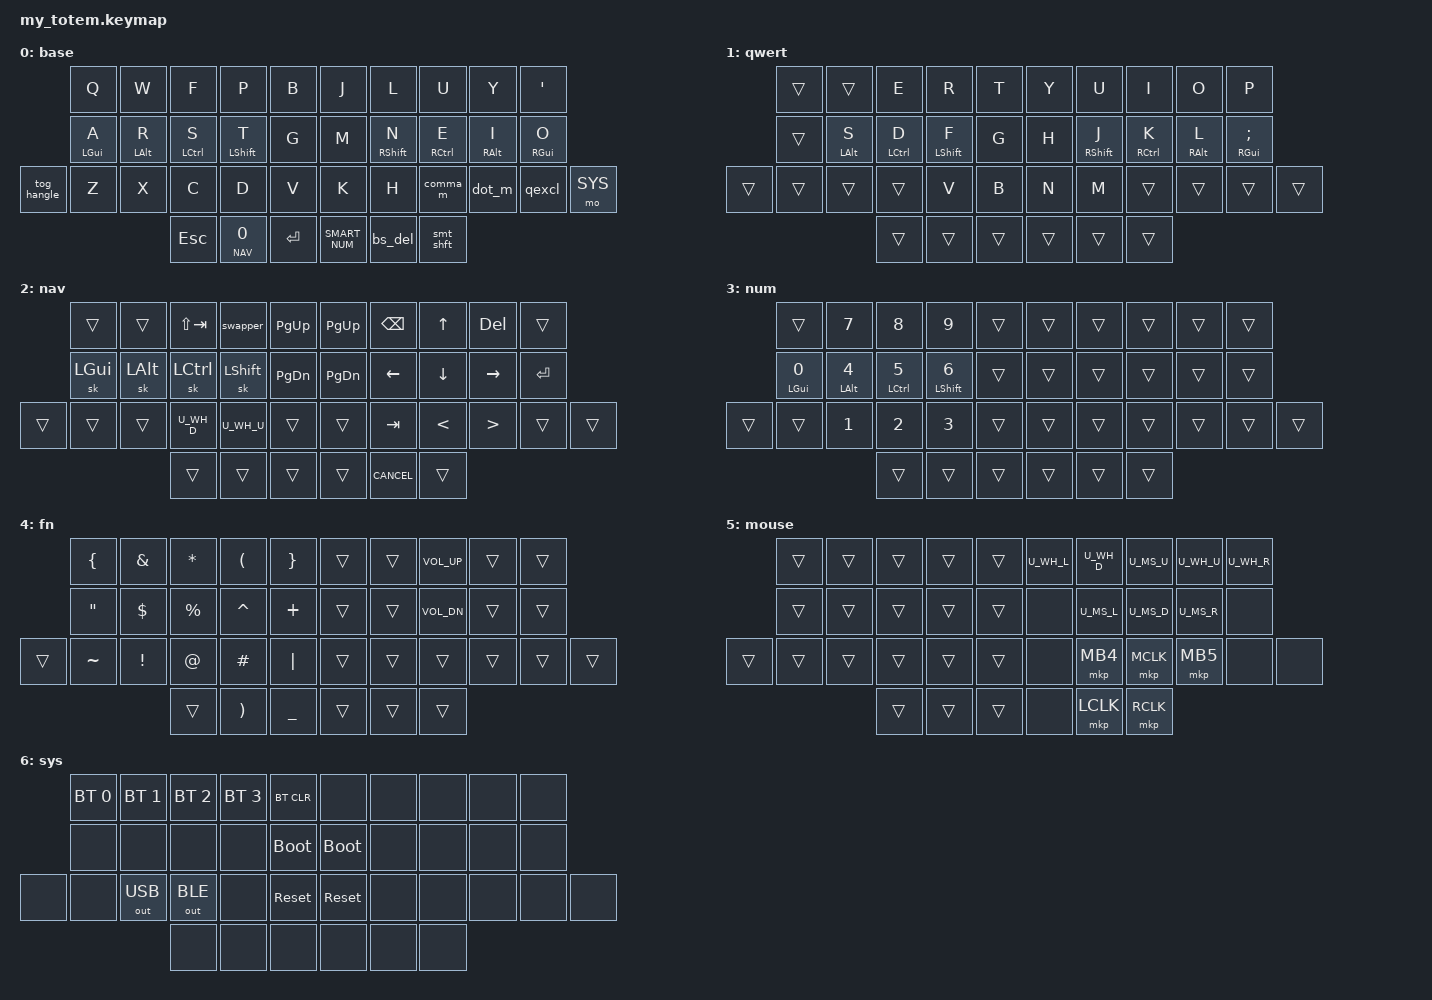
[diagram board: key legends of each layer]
//
//                                                        ▀▀▀▀▀     ▀▀▀▀▀          ▀▀█▀▀
//                                                        ▄▀▀▀▄  ▄  ▄▀▀▀▄  ▄  ▄▀▀▀▄  █  ▄▀▀▀▄
//                                                        █   █  █  █   █  █  █   █  █  █   █
//                                                         ▀▀▀   █   ▀▀▀   █   ▀▀▀   ▀   ▀▀▀
//                                                               █      ▄▄▄█▄▄▄    █   █  
//                                                               ▀      █  █  █     █▄█
//                                                             ▀▀▀▀▀    █  █  █      ▀
//                                                                      ▀  ▀  ▀
//
// ▄▄▄▄▄▄▄▄▄▄▄▄▄▄▄▄▄▄▄▄▄▄▄▄▄▄▄▄▄▄▄▄▄▄▄▄▄▄▄▄▄▄▄▄▄▄▄▄▄▄▄▄▄▄▄▄▄▄▄▄▄▄▄▄▄▄▄▄▄▄▄▄▄▄▄▄▄▄▄▄▄▄▄▄▄▄▄▄▄▄▄▄▄▄▄▄▄▄▄▄▄▄▄▄▄▄▄▄▄▄▄▄▄▄▄▄▄▄▄▄▄▄▄▄▄▄▄▄▄▄▄▄▄▄▄▄▄▄▄▄▄▄▄▄▄▄▄▄▄

#include <behaviors.dtsi>
#include <dt-bindings/zmk/bt.h>
#include <dt-bindings/zmk/keys.h>
#include <dt-bindings/zmk/outputs.h>
#include "keypos_38keys.h"

#include "zmk-helpers/helper.h"

#define BASE 0
#define QWERT 1
#define NAV 2
#define NUM 3
#define FN 4
#define MOUSE 5
#define SYS 6

#define KEYS_L LT0 LT1 LT2 LT3 LT4 LM0 LM1 LM2 LM3 LM4 LB0 LB1 LB2 LB3 LB4 LB5  // left hand
#define KEYS_R RT0 RT1 RT2 RT3 RT4 RM0 RM1 RM2 RM3 RM4 RB0 RB1 RB2 RB3 RB4 RB5  // right hand
#define THUMBS LH2 LH1 LH0 RH0 RH1 RH2                                          // thumbs
                                                                                
#include "combos.dtsi"
#include "mouse.dtsi"

#define XXX &none
#define ___ &trans

/* Global settings */
#define QUICK_TAP_MS 175
#define TAPPING_TERM_MS 200

#include "behaviors.dtsi"
#include "macros.dtsi"

/* Nav cluster */
#define NAV_LEFT  &mt_home 0   LEFT    // tap: left  | long-tap: beginning of line
#define NAV_RIGHT &mt_end 0    RIGHT   // tap: right | long-tap: end       of line
#define NAV_UP    &mt LC(HOME) UP      // tap: up    | long-tap: beginning of document
#define NAV_DOWN  &mt LC(END)  DOWN    // tap: down  | long-tap: end       of document
#define NAV_BSPC  &mt LC(BSPC) BSPC    // tap: bspc  | long-tap: delete word backward
#define NAV_DEL   &mt LC(DEL)  DEL     // tap: del   | long-tap: delete word forward

ZMK_CONDITIONAL_LAYER(FN NUM, SYS)     // FN + NUM --> SYS

ZMK_LAYER(base,
//                 ╭───────────────┬───────────────┬───────────────┬───────────────┬───────────────╮   ╭───────────────┬───────────────┬───────────────┬───────────────┬───────────────╮
                     &kp Q           &kp W           &kp F           &kp P           &kp B               &kp J           &kp L           &kp U           &kp Y           &kp SQT
//                 ├───────────────┼───────────────┼───────────────┼───────────────┼───────────────┤   ├───────────────├───────────────┼───────────────┼───────────────┼───────────────┤
                     &hml LGUI A     &hml LALT R     &hml LCTRL S    &hml LSHFT T    &kp G               &kp M           &hmr RSHFT N    &hmr RCTRL E    &hmr RALT I     &hmr RGUI O
// ╭───────────────┼───────────────┼───────────────┼───────────────┼───────────────┼───────────────┤   ├───────────────├───────────────┼───────────────┼───────────────┼───────────────┤───────────────╮
     &tog_hangle     &kp Z           &kp X           &kp C           &kp D           &kp V               &kp K           &kp H           &comma_m        &dot_m          &qexcl          &mo SYS
// ╰───────────────┴───────────────┴───────────────┼───────────────┼───────────────┼───────────────┤   ├───────────────├───────────────┼───────────────┼───────────────┴───────────────┴───────────────╯
                                                     &kp ESC         &lt_spc NAV 0   &kp  RETURN        SMART_NUM       &bs_del         &smt_shft
//                                                 ╰───────────────┴───────────────┴───────────────╯   ╰───────────────┴───────────────┴───────────────╯
)
ZMK_LAYER(qwert,
//                 ╭───────────────┬───────────────┬───────────────┬───────────────┬───────────────╮   ╭───────────────┬───────────────┬───────────────┬───────────────┬───────────────╮
                     ___             ___             &kp E           &kp R           &kp T               &kp Y           &kp U           &kp I           &kp O           &kp P
//                 ├───────────────┼───────────────┼───────────────┼───────────────┼───────────────┤   ├───────────────├───────────────┼───────────────┼───────────────┼───────────────┤
                     ___             &hml LALT S     &hml LCTRL D    &hml LSHFT F    &kp G               &kp H           &hmr RSHFT J    &hmr RCTRL K    &hmr RALT L    &hmr RGUI SEMI
// ╭───────────────┼───────────────┼───────────────┼───────────────┼───────────────┼───────────────┤   ├───────────────├───────────────┼───────────────┼───────────────┼───────────────┤───────────────╮
     ___             ___             ___             ___             &kp V           &kp B               &kp N           &kp M           ___             ___             ___             ___
// ╰───────────────┴───────────────┴───────────────┼───────────────┼───────────────┼───────────────┤   ├───────────────├───────────────┼───────────────┼───────────────┴───────────────┴───────────────╯
                                                     ___             ___             ___                 ___             ___             ___
//                                                 ╰───────────────┴───────────────┴───────────────╯   ╰───────────────┴───────────────┴───────────────╯
)

ZMK_LAYER(nav,
//                 ╭───────────────┬───────────────┬───────────────┬───────────────┬───────────────╮   ╭───────────────┬───────────────┬───────────────┬───────────────┬───────────────╮
                     ___             ___             &kp LS(TAB)     &swapper        &kp PG_UP           &kp PG_UP       &kp BSPC        &kp UP          &kp DEL         ___
//                 ├───────────────┼───────────────┼───────────────┼───────────────┼───────────────┤   ├───────────────├───────────────┼───────────────┼───────────────┼───────────────┤
                     &sk LGUI        &sk LALT        &sk LCTRL       &sk LSHIFT      &kp PG_DN           &kp PG_DN       &kp LEFT        &kp DOWN        &kp RIGHT       &kp RET
// ╭───────────────┼───────────────┼───────────────┼───────────────┼───────────────┼───────────────┤   ├───────────────├───────────────┼───────────────┼───────────────┼───────────────┤───────────────╮
     ___             ___             ___             U_WH_D          U_WH_U          ___                 ___             &kp TAB         &kp LT          &kp GT          ___             ___
// ╰───────────────┴───────────────┴───────────────┼───────────────┼───────────────┼───────────────┤   ├───────────────├───────────────┼───────────────┼───────────────┴───────────────┴───────────────╯
                                                     ___             ___             ___                 ___             &kp K_CANCEL    ___
//                                                 ╰───────────────┴───────────────┴───────────────╯   ╰───────────────┴───────────────┴───────────────╯
)
ZMK_LAYER(num,
//                 ╭───────────────┬───────────────┬───────────────┬───────────────┬───────────────╮   ╭───────────────┬───────────────┬───────────────┬───────────────┬───────────────╮
                     ___             &kp N7          &kp N8          &kp N9          ___                 ___             ___             ___             ___             ___
//                 ├───────────────┼───────────────┼───────────────┼───────────────┼───────────────┤   ├───────────────├───────────────┼───────────────┼───────────────┼───────────────┤
                     &hml LGUI N0    &hml LALT N4    &hml LCTRL N5   &hml LSHFT N6   ___                 ___             ___             ___             ___             ___
// ╭───────────────┼───────────────┼───────────────┼───────────────┼───────────────┼───────────────┤   ├───────────────├───────────────┼───────────────┼───────────────┼───────────────┤───────────────╮
     ___             ___             &kp N1          &kp N2          &kp N3          ___                 ___             ___             ___             ___             ___             ___
// ╰───────────────┴───────────────┴───────────────┼───────────────┼───────────────┼───────────────┤   ├───────────────├───────────────┼───────────────┼───────────────┴───────────────┴───────────────╯
                                                     ___             ___             ___                 ___             ___             ___
//                                                 ╰───────────────┴───────────────┴───────────────╯   ╰───────────────┴───────────────┴───────────────╯
)
ZMK_LAYER(fn,
//                 ╭───────────────┬───────────────┬───────────────┬───────────────┬───────────────╮   ╭───────────────┬───────────────┬───────────────┬───────────────┬───────────────╮
                     &kp LBRC        &kp AMPS        &kp ASTRK       &kp LPAR        &kp RBRC            ___             ___             &kp C_VOL_UP    ___             ___
//                 ├───────────────┼───────────────┼───────────────┼───────────────┼───────────────┤   ├───────────────├───────────────┼───────────────┼───────────────┼───────────────┤
                     &kp DQT         &kp DLLR        &kp PRCNT       &kp CARET       &kp PLUS            ___             ___             &kp C_VOL_DN    ___             ___
// ╭───────────────┼───────────────┼───────────────┼───────────────┼───────────────┼───────────────┤   ├───────────────├───────────────┼───────────────┼───────────────┼───────────────┤───────────────╮
     ___             &kp TILDE       &kp EXCL        &kp AT_SIGN     &kp HASH        &kp PIPE            ___             ___             ___             ___             ___             ___
// ╰───────────────┴───────────────┴───────────────┼───────────────┼───────────────┼───────────────┤   ├───────────────├───────────────┼───────────────┼───────────────┴───────────────┴───────────────╯
                                                     ___             &kp RPAR        &kp UNDER           ___             ___             ___
//                                                 ╰───────────────┴───────────────┴───────────────╯   ╰───────────────┴───────────────┴───────────────╯
)
ZMK_LAYER(mouse,
//                 ╭───────────────┬───────────────┬───────────────┬───────────────┬───────────────╮   ╭───────────────┬───────────────┬───────────────┬───────────────┬───────────────╮
                     ___             ___             ___             ___             ___                 U_WH_L          U_WH_D          U_MS_U          U_WH_U          U_WH_R  
//                 ├───────────────┼───────────────┼───────────────┼───────────────┼───────────────┤   ├───────────────├───────────────┼───────────────┼───────────────┼───────────────┤
                     ___             ___             ___             ___             ___                 XXX             U_MS_L          U_MS_D          U_MS_R          XXX  
// ╭───────────────┼───────────────┼───────────────┼───────────────┼───────────────┼───────────────┤   ├───────────────├───────────────┼───────────────┼───────────────┼───────────────┤───────────────╮
     ___             ___             ___             ___             ___             ___                 XXX             &mkp MB4        &mkp MCLK       &mkp MB5        XXX             XXX
// ╰───────────────┴───────────────┴───────────────┼───────────────┼───────────────┼───────────────┤   ├───────────────├───────────────┼───────────────┼───────────────┴───────────────┴───────────────╯
                                                     ___             ___             ___                 XXX             &mkp LCLK       &mkp RCLK
//                                                 ╰───────────────┴───────────────┴───────────────╯   ╰───────────────┴───────────────┴───────────────╯

)
ZMK_LAYER(sys,
//                 ╭───────────────┬───────────────┬───────────────┬───────────────┬───────────────╮   ╭───────────────┬───────────────┬───────────────┬───────────────┬───────────────╮
                     &bt BT_SEL 0    &bt BT_SEL 1    &bt BT_SEL 2    &bt BT_SEL 3    &bt BT_CLR          XXX             XXX             XXX             XXX             XXX
//                 ├───────────────┼───────────────┼───────────────┼───────────────┼───────────────┤   ├───────────────├───────────────┼───────────────┼───────────────┼───────────────┤
                     XXX             XXX             XXX             XXX             &bootloader         &bootloader     XXX             XXX             XXX             XXX
// ╭───────────────┼───────────────┼───────────────┼───────────────┼───────────────┼───────────────┤   ├───────────────├───────────────┼───────────────┼───────────────┼───────────────┤───────────────╮
     XXX             XXX             &out OUT_USB    &out OUT_BLE    XXX             &sys_reset          &sys_reset      XXX             XXX             XXX             XXX             XXX
// ╰───────────────┴───────────────┴───────────────┼───────────────┼───────────────┼───────────────┤   ├───────────────├───────────────┼───────────────┼───────────────┴───────────────┴───────────────╯
                                                     XXX             XXX             XXX                 XXX             XXX             XXX
//                                                 ╰───────────────┴───────────────┴───────────────╯   ╰───────────────┴───────────────┴───────────────╯
)
// / {
//     keymap {
//         compatible = "zmk,keymap";
// // ▄▄▄▄▄▄▄▄▄▄▄▄▄▄▄▄▄▄▄▄▄▄▄▄▄▄▄▄▄▄▄▄▄▄▄▄▄▄▄▄▄▄▄▄▄▄▄▄▄▄▄▄▄▄▄▄▄▄▄▄▄▄▄▄▄▄▄▄▄▄▄▄▄▄▄▄▄▄▄▄▄▄▄▄▄▄▄▄▄▄▄▄▄▄▄▄▄▄▄▄▄▄▄▄▄▄▄▄▄▄▄▄▄▄▄▄▄▄▄▄▄▄▄▄▄▄▄▄▄▄▄▄▄▄▄▄▄▄▄▄▄▄▄▄▄▄▄▄▄
//
//         base_layer {
//             bindings = <
// //                 ╭───────────────┬───────────────┬───────────────┬───────────────┬───────────────╮   ╭───────────────┬───────────────┬───────────────┬───────────────┬───────────────╮
//                      &kp Q           &kp W           &kp F           &kp P           &kp B               &kp J           &kp L           &kp U           &kp Y           &kp SQT
// //                 ├───────────────┼───────────────┼───────────────┼───────────────┼───────────────┤   ├───────────────├───────────────┼───────────────┼───────────────┼───────────────┤
//                      &hml LGUI A     &hml LALT R     &hml LCTRL S    &hml LSHFT T    &kp G               &kp M           &hmr RSHFT N    &hmr RCTRL E    &hmr RALT I     &hmr RGUI O
// // ╭───────────────┼───────────────┼───────────────┼───────────────┼───────────────┼───────────────┤   ├───────────────├───────────────┼───────────────┼───────────────┼───────────────┤───────────────╮
//      &tog_hangle     &kp Z           &kp X           &kp C           &kp D           &kp V               &kp K           &kp H           &comma_m        &dot_m          &qexcl          &mo SYS
// // ╰───────────────┴───────────────┴───────────────┼───────────────┼───────────────┼───────────────┤   ├───────────────├───────────────┼───────────────┼───────────────┴───────────────┴───────────────╯
//                                                      &kp ESC         &lt_spc NAV 0   &kp  RETURN        SMART_NUM       &bs_del         &smt_shft
// //                                                 ╰───────────────┴───────────────┴───────────────╯   ╰───────────────┴───────────────┴───────────────╯
//             >;
//         };
// // ▄▄▄▄▄▄▄▄▄▄▄▄▄▄▄▄▄▄▄▄▄▄▄▄▄▄▄▄▄▄▄▄▄▄▄▄▄▄▄▄▄▄▄▄▄▄▄▄▄▄▄▄▄▄▄▄▄▄▄▄▄▄▄▄▄▄▄▄▄▄▄▄▄▄▄▄▄▄▄▄▄▄▄▄▄▄▄▄▄▄▄▄▄▄▄▄▄▄▄▄▄▄▄▄▄▄▄▄▄▄▄▄▄▄▄▄▄▄▄▄▄▄▄▄▄▄▄▄▄▄▄▄▄▄▄▄▄▄▄▄▄▄▄▄▄▄▄▄▄
//
//         qwert_layout {
//             bindings = <
// //                 ╭───────────────┬───────────────┬───────────────┬───────────────┬───────────────╮   ╭───────────────┬───────────────┬───────────────┬───────────────┬───────────────╮
//                      ___             ___             &kp E           &kp R           &kp T               &kp Y           &kp U           &kp I           &kp O           &kp P
// //                 ├───────────────┼───────────────┼───────────────┼───────────────┼───────────────┤   ├───────────────├───────────────┼───────────────┼───────────────┼───────────────┤
//                      ___             &hml LALT S     &hml LCTRL D    &hml LSHFT F    &kp G               &kp H           &hmr RSHFT J    &hmr RCTRL K    &hmr RALT L    &hmr RGUI SEMI
// // ╭───────────────┼───────────────┼───────────────┼───────────────┼───────────────┼───────────────┤   ├───────────────├───────────────┼───────────────┼───────────────┼───────────────┤───────────────╮
//      ___             ___             ___             ___             &kp V           &kp B               &kp N           &kp M           ___             ___             ___             ___
// // ╰───────────────┴───────────────┴───────────────┼───────────────┼───────────────┼───────────────┤   ├───────────────├───────────────┼───────────────┼───────────────┴───────────────┴───────────────╯
//                                                      ___             ___             ___                 ___             ___             ___
// //                                                 ╰───────────────┴───────────────┴───────────────╯   ╰───────────────┴───────────────┴───────────────╯
//             >;
//         };
// ▄▄▄▄▄▄▄▄▄▄▄▄▄▄▄▄▄▄▄▄▄▄▄▄▄▄▄▄▄▄▄▄▄▄▄▄▄▄▄▄▄▄▄▄▄▄▄▄▄▄▄▄▄▄▄▄▄▄▄▄▄▄▄▄▄▄▄▄▄▄▄▄▄▄▄▄▄▄▄▄▄▄▄▄▄▄▄▄▄▄▄▄▄▄▄▄▄▄▄▄▄▄▄▄▄▄▄▄▄▄▄▄▄▄▄▄▄▄▄▄▄▄▄▄▄▄▄▄▄▄▄▄▄▄▄▄▄▄▄▄▄▄▄▄▄▄▄▄▄

//         nav_layer {
//             bindings = <
// //                 ╭───────────────┬───────────────┬───────────────┬───────────────┬───────────────╮   ╭───────────────┬───────────────┬───────────────┬───────────────┬───────────────╮
//                      ___             ___             &kp LS(TAB)     &swapper        &kp PG_UP           &kp PG_UP       &kp BSPC        &kp UP          &kp DEL         ___
// //                 ├───────────────┼───────────────┼───────────────┼───────────────┼───────────────┤   ├───────────────├───────────────┼───────────────┼───────────────┼───────────────┤
//                      &sk LGUI        &sk LALT        &sk LCTRL       &sk LSHIFT      &kp PG_DN           &kp PG_DN       &kp LEFT        &kp DOWN        &kp RIGHT       &kp RET
// // ╭───────────────┼───────────────┼───────────────┼───────────────┼───────────────┼───────────────┤   ├───────────────├───────────────┼───────────────┼───────────────┼───────────────┤───────────────╮
//      ___             ___             ___             U_WH_D          U_WH_U          ___                 ___             &kp TAB         &kp LT          &kp GT          ___             ___
// // ╰───────────────┴───────────────┴───────────────┼───────────────┼───────────────┼───────────────┤   ├───────────────├───────────────┼───────────────┼───────────────┴───────────────┴───────────────╯
//                                                      ___             ___             ___                 ___             &kp K_CANCEL    ___
// //                                                 ╰───────────────┴───────────────┴───────────────╯   ╰───────────────┴───────────────┴───────────────╯
//             >;
//         };
// ▄▄▄▄▄▄▄▄▄▄▄▄▄▄▄▄▄▄▄▄▄▄▄▄▄▄▄▄▄▄▄▄▄▄▄▄▄▄▄▄▄▄▄▄▄▄▄▄▄▄▄▄▄▄▄▄▄▄▄▄▄▄▄▄▄▄▄▄▄▄▄▄▄▄▄▄▄▄▄▄▄▄▄▄▄▄▄▄▄▄▄▄▄▄▄▄▄▄▄▄▄▄▄▄▄▄▄▄▄▄▄▄▄▄▄▄▄▄▄▄▄▄▄▄▄▄▄▄▄▄▄▄▄▄▄▄▄▄▄▄▄▄▄▄▄▄▄▄▄

//         num_layout {
//             bindings = <
// //                 ╭───────────────┬───────────────┬───────────────┬───────────────┬───────────────╮   ╭───────────────┬───────────────┬───────────────┬───────────────┬───────────────╮
//                      ___             &kp N7          &kp N8          &kp N9          ___                 ___             ___             ___             ___             ___
// //                 ├───────────────┼───────────────┼───────────────┼───────────────┼───────────────┤   ├───────────────├───────────────┼───────────────┼───────────────┼───────────────┤
//                      &hml LGUI N0    &hml LALT N4    &hml LCTRL N5   &hml LSHFT N6   ___                 ___             ___             ___             ___             ___
// // ╭───────────────┼───────────────┼───────────────┼───────────────┼───────────────┼───────────────┤   ├───────────────├───────────────┼───────────────┼───────────────┼───────────────┤───────────────╮
//      ___             ___             &kp N1          &kp N2          &kp N3          ___                 ___             ___             ___             ___             ___             ___
// // ╰───────────────┴───────────────┴───────────────┼───────────────┼───────────────┼───────────────┤   ├───────────────├───────────────┼───────────────┼───────────────┴───────────────┴───────────────╯
//                                                      ___             ___             ___                 ___             ___             ___
// //                                                 ╰───────────────┴───────────────┴───────────────╯   ╰───────────────┴───────────────┴───────────────╯
//             >;
//         };
// ▄▄▄▄▄▄▄▄▄▄▄▄▄▄▄▄▄▄▄▄▄▄▄▄▄▄▄▄▄▄▄▄▄▄▄▄▄▄▄▄▄▄▄▄▄▄▄▄▄▄▄▄▄▄▄▄▄▄▄▄▄▄▄▄▄▄▄▄▄▄▄▄▄▄▄▄▄▄▄▄▄▄▄▄▄▄▄▄▄▄▄▄▄▄▄▄▄▄▄▄▄▄▄▄▄▄▄▄▄▄▄▄▄▄▄▄▄▄▄▄▄▄▄▄▄▄▄▄▄▄▄▄▄▄▄▄▄▄▄▄▄▄▄▄▄▄▄▄▄

//         fn_layer {
//             bindings = <
// //                 ╭───────────────┬───────────────┬───────────────┬───────────────┬───────────────╮   ╭───────────────┬───────────────┬───────────────┬───────────────┬───────────────╮
//                      &kp LBRC        &kp AMPS        &kp ASTRK       &kp LPAR        &kp RBRC            ___             ___             &kp C_VOL_UP    ___             ___
// //                 ├───────────────┼───────────────┼───────────────┼───────────────┼───────────────┤   ├───────────────├───────────────┼───────────────┼───────────────┼───────────────┤
//                      &kp DQT         &kp DLLR        &kp PRCNT       &kp CARET       &kp PLUS            ___             ___             &kp C_VOL_DN    ___             ___
// // ╭───────────────┼───────────────┼───────────────┼───────────────┼───────────────┼───────────────┤   ├───────────────├───────────────┼───────────────┼───────────────┼───────────────┤───────────────╮
//      ___             &kp TILDE       &kp EXCL        &kp AT_SIGN     &kp HASH        &kp PIPE            ___             ___             ___             ___             ___             ___
// // ╰───────────────┴───────────────┴───────────────┼───────────────┼───────────────┼───────────────┤   ├───────────────├───────────────┼───────────────┼───────────────┴───────────────┴───────────────╯
//                                                      ___             &kp RPAR        &kp UNDER           ___             ___             ___
// //                                                 ╰───────────────┴───────────────┴───────────────╯   ╰───────────────┴───────────────┴───────────────╯
//             >;
//         };
// ▄▄▄▄▄▄▄▄▄▄▄▄▄▄▄▄▄▄▄▄▄▄▄▄▄▄▄▄▄▄▄▄▄▄▄▄▄▄▄▄▄▄▄▄▄▄▄▄▄▄▄▄▄▄▄▄▄▄▄▄▄▄▄▄▄▄▄▄▄▄▄▄▄▄▄▄▄▄▄▄▄▄▄▄▄▄▄▄▄▄▄▄▄▄▄▄▄▄▄▄▄▄▄▄▄▄▄▄▄▄▄▄▄▄▄▄▄▄▄▄▄▄▄▄▄▄▄▄▄▄▄▄▄▄▄▄▄▄▄▄▄▄▄▄▄▄▄▄▄

//         mouse_layout {
//             bindings = <
// //                 ╭───────────────┬───────────────┬───────────────┬───────────────┬───────────────╮   ╭───────────────┬───────────────┬───────────────┬───────────────┬───────────────╮
//                      ___             ___             ___             ___             ___                 U_WH_L          U_WH_D          U_MS_U          U_WH_U          U_WH_R  
// //                 ├───────────────┼───────────────┼───────────────┼───────────────┼───────────────┤   ├───────────────├───────────────┼───────────────┼───────────────┼───────────────┤
//                      ___             ___             ___             ___             ___                 XXX             U_MS_L          U_MS_D          U_MS_R          XXX  
// // ╭───────────────┼───────────────┼───────────────┼───────────────┼───────────────┼───────────────┤   ├───────────────├───────────────┼───────────────┼───────────────┼───────────────┤───────────────╮
//      ___             ___             ___             ___             ___             ___                 XXX             &mkp MB4        &mkp MCLK       &mkp MB5        XXX             XXX
// // ╰───────────────┴───────────────┴───────────────┼───────────────┼───────────────┼───────────────┤   ├───────────────├───────────────┼───────────────┼───────────────┴───────────────┴───────────────╯
//                                                      ___             ___             ___                 XXX             &mkp LCLK       &mkp RCLK
// //                                                 ╰───────────────┴───────────────┴───────────────╯   ╰───────────────┴───────────────┴───────────────╯
//             >;
//         };
// ▄▄▄▄▄▄▄▄▄▄▄▄▄▄▄▄▄▄▄▄▄▄▄▄▄▄▄▄▄▄▄▄▄▄▄▄▄▄▄▄▄▄▄▄▄▄▄▄▄▄▄▄▄▄▄▄▄▄▄▄▄▄▄▄▄▄▄▄▄▄▄▄▄▄▄▄▄▄▄▄▄▄▄▄▄▄▄▄▄▄▄▄▄▄▄▄▄▄▄▄▄▄▄▄▄▄▄▄▄▄▄▄▄▄▄▄▄▄▄▄▄▄▄▄▄▄▄▄▄▄▄▄▄▄▄▄▄▄▄▄▄▄▄▄▄▄▄▄▄

//         sys_layer {
//             bindings = <
// //                 ╭───────────────┬───────────────┬───────────────┬───────────────┬───────────────╮   ╭───────────────┬───────────────┬───────────────┬───────────────┬───────────────╮
//                      &bt BT_SEL 0    &bt BT_SEL 1    &bt BT_SEL 2    &bt BT_SEL 3    &bt BT_CLR          XXX             XXX             XXX             XXX             XXX
// //                 ├───────────────┼───────────────┼───────────────┼───────────────┼───────────────┤   ├───────────────├───────────────┼───────────────┼───────────────┼───────────────┤
//                      XXX             XXX             XXX             XXX             &bootloader         &bootloader     XXX             XXX             XXX             XXX
// // ╭───────────────┼───────────────┼───────────────┼───────────────┼───────────────┼───────────────┤   ├───────────────├───────────────┼───────────────┼───────────────┼───────────────┤───────────────╮
//      XXX             XXX             &out OUT_USB    &out OUT_BLE    XXX             &sys_reset          &sys_reset      XXX             XXX             XXX             XXX             XXX
// // ╰───────────────┴───────────────┴───────────────┼───────────────┼───────────────┼───────────────┤   ├───────────────├───────────────┼───────────────┼───────────────┴───────────────┴───────────────╯
//                                                      XXX             XXX             XXX                 XXX             XXX             XXX
// //                                                 ╰───────────────┴───────────────┴───────────────╯   ╰───────────────┴───────────────┴───────────────╯
//             >;
//         };
//     };
// };
